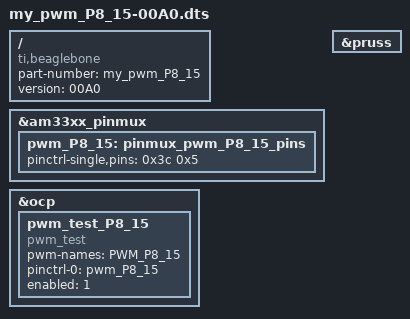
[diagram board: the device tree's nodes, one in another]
/dts-v1/;
/plugin/;

/ {
	compatible = "ti,beaglebone", "ti,beaglebone-black";

	/* identification */
	part-number = "my_pwm_P8_15";
	version = "00A0";

	fragment@0 {
		target = <&am33xx_pinmux>;
		__overlay__ {
			pwm_P8_15: pinmux_pwm_P8_15_pins {
				pinctrl-single,pins = <0x3c  0x5>;
			};
		};
	};

	fragment@1 {
		target = <&ocp>;
		__overlay__ {
			pwm_test_P8_15 {
				compatible	= "pwm_test";
				pwm-names 	= "PWM_P8_15";
				pinctrl-names	= "default";
				pinctrl-0	= <&pwm_P8_15>;
				enabled		= <1>;
				status 		= "okay";
			};
		};
	};

 	fragment@2 {
  		   target = <&pruss>;
		   __overlay__ {
		   	       status = "okay";

    	           };
        };

};
